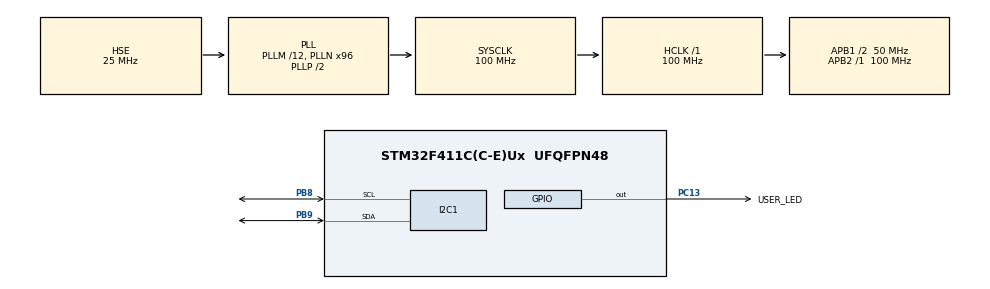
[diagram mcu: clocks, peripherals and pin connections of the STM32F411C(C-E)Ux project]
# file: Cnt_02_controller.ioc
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Mcu.Family=STM32F4
Mcu.Name=STM32F411C(C-E)Ux
Mcu.Package=UFQFPN48
NVIC.PriorityGroup=NVIC_PRIORITYGROUP_4
NVIC.TIM1_UP_TIM10_IRQn=true\:0\:0\:false\:false\:true\:true\:true
PB8.Mode=I2C
PB8.Signal=I2C1_SCL
PB9.Mode=I2C
PB9.Signal=I2C1_SDA
PC13-ANTI_TAMP.GPIO_Label=USER_LED
PC13-ANTI_TAMP.Signal=GPIO_Output
PC14-OSC32_IN.Mode=LSE-External-Oscillator
PC14-OSC32_IN.Signal=RCC_OSC32_IN
PC15-OSC32_OUT.Mode=LSE-External-Oscillator
PC15-OSC32_OUT.Signal=RCC_OSC32_OUT
PH0\ -\ OSC_IN.Mode=HSE-External-Oscillator
PH0\ -\ OSC_IN.Signal=RCC_OSC_IN
PH1\ -\ OSC_OUT.Mode=HSE-External-Oscillator
PH1\ -\ OSC_OUT.Signal=RCC_OSC_OUT
ProjectManager.HeapSize=0x200
ProjectManager.StackSize=0x400
ProjectManager.TargetToolchain=STM32CubeIDE
RCC.48MHZClocksFreq_Value=50000000
RCC.AHBFreq_Value=100000000
RCC.APB1CLKDivider=RCC_HCLK_DIV2
RCC.APB1Freq_Value=50000000
RCC.APB1TimFreq_Value=100000000
RCC.APB2Freq_Value=100000000
RCC.APB2TimFreq_Value=100000000
RCC.CortexFreq_Value=100000000
RCC.HCLKFreq_Value=100000000
RCC.HSE_VALUE=25000000
RCC.HSI_VALUE=16000000
RCC.PLLM=12
RCC.PLLN=96
RCC.PLLSourceVirtual=RCC_PLLSOURCE_HSE
RCC.SYSCLKFreq_VALUE=100000000
RCC.SYSCLKSource=RCC_SYSCLKSOURCE_PLLCLK
RCC.VCOOutputFreq_Value=200000000
TIM10.ClockDivision=TIM_CLOCKDIVISION_DIV1
TIM10.Period=9999
TIM10.Prescaler=9999
VP_TIM10_VS_ClockSourceINT.Mode=Enable_Timer
board=custom

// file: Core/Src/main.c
/* USER CODE BEGIN Header */
/**
  ******************************************************************************
  * @file           : main.c
  * @brief          : Main program body of controller GPIO in project "free_michelle"
  ******************************************************************************

  ******************************************************************************
  */
/* USER CODE END Header */
#include "main.h"
#include "i2c.h"
#include "tim.h"
#include "gpio.h"

/* USER CODE BEGIN Includes */
#include "bmp280.h"
/* USER CODE END Includes */

/* USER CODE BEGIN PV */
BMP280_t Bmp280;
/* USER CODE END PV */

void SystemClock_Config(void);
/* USER CODE BEGIN PFP */
void HAL_TIM_PeriodElapsedCallback(TIM_HandleTypeDef *htim);
/* USER CODE END PFP */

int main(void)
{

  /* MCU Configuration--------------------------------------------------------*/

  /* Reset of all peripherals, Initializes the Flash interface and the Systick. */
  HAL_Init();

  /* Configure the system clock */
  SystemClock_Config();

  /* Initialize all configured peripherals */
  MX_GPIO_Init();
  MX_I2C1_Init();
  MX_TIM10_Init();
  /* USER CODE BEGIN 2 */
  BMP280_Init(&Bmp280, &hi2c1, BMP280_ADDRESS);
  float Temp, Pressure;
  /* USER CODE END 2 */

  /* Infinite loop */
  while (1)
  {

  }
}

void SystemClock_Config(void)
{
  RCC_OscInitTypeDef RCC_OscInitStruct = {0};
  RCC_ClkInitTypeDef RCC_ClkInitStruct = {0};

  /** Configure the main internal regulator output voltage
  */
  __HAL_RCC_PWR_CLK_ENABLE();
  __HAL_PWR_VOLTAGESCALING_CONFIG(PWR_REGULATOR_VOLTAGE_SCALE1);
  /** Initializes the RCC Oscillators according to the specified parameters
  * in the RCC_OscInitTypeDef structure.
  */
  RCC_OscInitStruct.OscillatorType = RCC_OSCILLATORTYPE_HSE;
  RCC_OscInitStruct.HSEState = RCC_HSE_ON;
  RCC_OscInitStruct.PLL.PLLState = RCC_PLL_ON;
  RCC_OscInitStruct.PLL.PLLSource = RCC_PLLSOURCE_HSE;
  RCC_OscInitStruct.PLL.PLLM = 12;
  RCC_OscInitStruct.PLL.PLLN = 96;
  RCC_OscInitStruct.PLL.PLLP = RCC_PLLP_DIV2;
  RCC_OscInitStruct.PLL.PLLQ = 4;
  if (HAL_RCC_OscConfig(&RCC_OscInitStruct) != HAL_OK)
  {
    Error_Handler();
  }
  /** Initializes the CPU, AHB and APB buses clocks
  */
  RCC_ClkInitStruct.ClockType = RCC_CLOCKTYPE_HCLK|RCC_CLOCKTYPE_SYSCLK
                              |RCC_CLOCKTYPE_PCLK1|RCC_CLOCKTYPE_PCLK2;
  RCC_ClkInitStruct.SYSCLKSource = RCC_SYSCLKSOURCE_PLLCLK;
  RCC_ClkInitStruct.AHBCLKDivider = RCC_SYSCLK_DIV1;
  RCC_ClkInitStruct.APB1CLKDivider = RCC_HCLK_DIV2;
  RCC_ClkInitStruct.APB2CLKDivider = RCC_HCLK_DIV1;

  if (HAL_RCC_ClockConfig(&RCC_ClkInitStruct, FLASH_LATENCY_3) != HAL_OK)
  {
    Error_Handler();
  }
}

/* USER CODE BEGIN 4 */
void HAL_TIM_PeriodElapsedCallback(TIM_HandleTypeDef *htim){
	if(htim->Instance == TIM10){ // Jeżeli przerwanie pochodzi od timera 10 [1s]
		  BMP280_ReadPressureAndTemperature(&Bmp280, &Pressure, &Temp); // wykonanie pomiaru temperatury i ciśnienia
		  HAL_GPIO_TogglePin(USER_LED_GPIO_Port, USER_LED_Pin);
	}
}
/* USER CODE END 4 */

void Error_Handler(void)
{
  __disable_irq();
  while (1)
  {
  }
}

/************************ (C) COPYRIGHT STMicroelectronics *****END OF FILE****/
